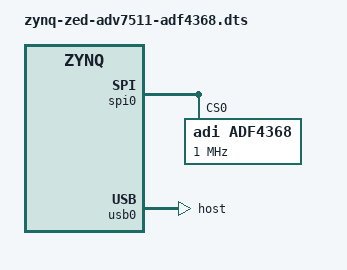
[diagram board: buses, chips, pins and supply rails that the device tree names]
// SPDX-License-Identifier: GPL-2.0

/dts-v1/;

#include "zynq-zed.dtsi"
#include "zynq-zed-adv7511.dtsi"

/ {
	clocks {
		adf4368_clkin: clock@0 {
		     #clock-cells = <0>;
		     compatible = "fixed-clock";
		     clock-frequency = <122880000>; // 122.88MHz
		};
	};
};


&spi0 {
	status = "okay";
	adf4368@0 {
		compatible = "adi,adf4368";
		reg = <0>;
		spi-max-frequency = <1000000>;		
		//#clock-cells = <0>;
		clock-output-names = "adf4368_out_clk";
		clocks = <&adf4368_clkin>;
		clock-names = "ref_clk";
		adi,charge-pump-microamp = /bits/ 8 <15>;
		adi,ref-divider = /bits/ 8 <1>;
		adi,ref-doubler-enable;
		adi,power-up-frequency = /bits/ 64 <5200000000>;
		// adi,spi-3wire-enable;
		/* spi-cpha; */
		/* spi-cpol; */
		/* #address-cells = <1>;
		#size-cells = <0>; */
	};
};

&usb0 {
	status = "okay";
	dr_mode = "host";
};
